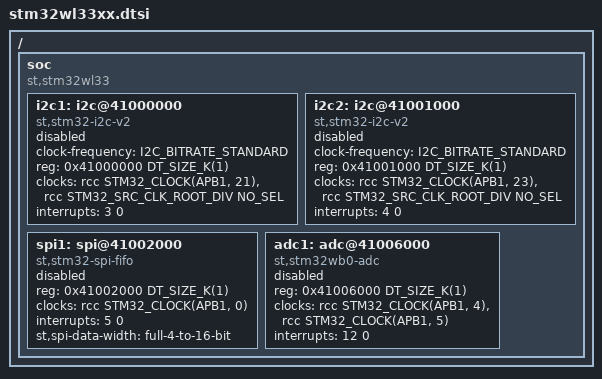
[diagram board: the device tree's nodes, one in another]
/*
 * Copyright (c) 2024 STMicroelectronics
 * Copyright (c) 2026 Anders Frandsen <anfran@anfran.dk>
 *
 * SPDX-License-Identifier: Apache-2.0
 */

#include <st/wl3/stm32wl3x.dtsi>
#include <zephyr/dt-bindings/adc/adc.h>

/ {
	soc {
		compatible = "st,stm32wl33", "st,stm32wl3", "simple-bus";

		i2c1: i2c@41000000 {
			compatible = "st,stm32-i2c-v2";
			clock-frequency = <I2C_BITRATE_STANDARD>;
			#address-cells = <1>;
			#size-cells = <0>;
			reg = <0x41000000 DT_SIZE_K(1)>;
			clocks = <&rcc STM32_CLOCK(APB1, 21)>,
				 <&rcc STM32_SRC_CLK_ROOT_DIV NO_SEL>;
			interrupts = <3 0>;
			interrupt-names = "combined";
			status = "disabled";
		};

		i2c2: i2c@41001000 {
			compatible = "st,stm32-i2c-v2";
			clock-frequency = <I2C_BITRATE_STANDARD>;
			#address-cells = <1>;
			#size-cells = <0>;
			reg = <0x41001000 DT_SIZE_K(1)>;
			clocks = <&rcc STM32_CLOCK(APB1, 23)>,
				 <&rcc STM32_SRC_CLK_ROOT_DIV NO_SEL>;
			interrupts = <4 0>;
			interrupt-names = "combined";
			status = "disabled";
		};

		spi1: spi@41002000 {
			compatible = "st,stm32-spi-fifo", "st,stm32-spi";
			#address-cells = <1>;
			#size-cells = <0>;
			reg = <0x41002000 DT_SIZE_K(1)>;
			clocks = <&rcc STM32_CLOCK(APB1, 0)>;
			interrupts = <5 0>;
			st,spi-data-width = "full-4-to-16-bit";
			status = "disabled";
		};

		adc1: adc@41006000 {
			compatible = "st,stm32wb0-adc";
			reg = <0x41006000 DT_SIZE_K(1)>;
			/* Digital (always-on) and analog (on-demand) ADC clock domains */
			clocks = <&rcc STM32_CLOCK(APB1, 4)>,
				 <&rcc STM32_CLOCK(APB1, 5)>;
			interrupts = <12 0>;
			#io-channel-cells = <1>;
			status = "disabled";
		};
	};
};
